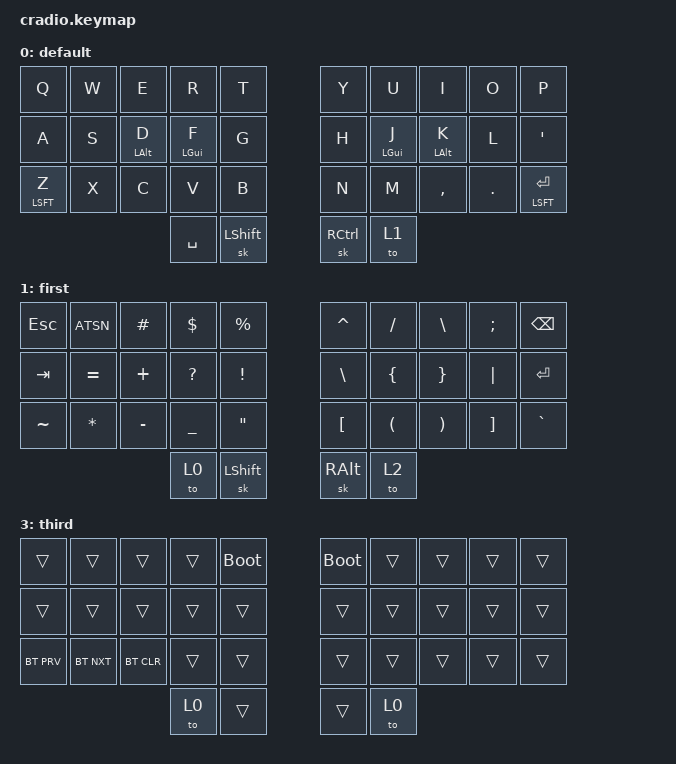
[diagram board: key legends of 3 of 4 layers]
/*
 * Copyright (c) 2020 The ZMK Contributors
 *
 * SPDX-License-Identifier: MIT
 */

#include <behaviors.dtsi>
#include <dt-bindings/zmk/keys.h>
#include <dt-bindings/zmk/bt.h>

&mt {
    flavor = "tap-preferred";
    tapping_term_ms = <200>;
};

/ {
    combos { compatible = "zmk,combos"; };

    keymap {
      compatible = "zmk,keymap";

      default {
        bindings = <
          &kp Q &kp W &kp E &kp R &kp T              &kp Y &kp U &kp I &kp O &kp P
          &kp A &kp S &mt LALT D &mt LGUI F &kp G    &kp H &mt LGUI J &mt LALT K &kp L &kp QUOT
          &mt LSFT Z &kp X &kp C &kp V &kp B         &kp N &kp M &kp CMMA &kp DOT &mt LSFT ENTER
          &kp SPC &sk LSHIFT                         &sk RCTRL &to 1
          >;
      };

      first {
        bindings = <
          &kp ESC &kp ATSN &kp HASH &kp DLLR &kp PRCNT     &kp CARET &kp SLASH &kp BSLH &kp SEMI &kp BKSP
          &kp TAB &kp EQUAL &kp PLUS &kp QMARK &kp EXCL    &kp BSLH &kp LBRC &kp RBRC &kp PIPE &kp ENTER
          &kp TILDE &kp STAR &kp MINUS &kp UNDER &kp DQT   &kp LBKT &kp LPRN &kp RPRN &kp RBKT &kp GRAVE
          &to 0 &sk LSHIFT                                 &sk RALT &to 2
          >;
      };

      second {
        bindings = <
          &kp ESC &kp C_PP &kp C_PREV &kp C_NEXT &kp &trans      &kp MINUS &kp N7 &kp N8 &kp N9 &trans
          &kp TAB &trans &kp C_VOL_DN &kp C_VOL_UP &kp &trans    &kp EQUAL &kp N4 &kp N5 &kp N6 &kp ENTER
          &trans &kp AMPS &kp SLASH &kp STAR &kp DOT             &kp N0 &kp N1 &kp N2 &kp N3 &trans
          &to 0 &sk LGUI                                         &sk RALT &to 3
          >;
      };

      third {
        bindings = <
          &trans &trans &trans &trans &bootloader           &bootloader &trans &trans &trans &trans
          &trans &trans &trans &trans &trans                &trans &trans &trans &trans &trans
          &bt BT_PRV &bt BT_NXT &bt BT_CLR &trans &trans    &trans &trans &trans &trans &trans
          &to 0 &trans                                      &trans &to 0
          >;
      };
    };
};
